# ESP32C6_RADIO register map
File version: 0.1.0
Registers are 32-bit, read-write, no defined reset value unless marked. A register's access mark holds for its fields unless they carry their own. Offsets are from the block's base; [hi:lo] are bit positions; <NAME> marks a mode.

## RFPLL — Analog I2C block 0x62 (RF PLL) The RF PLL's VCO and its calibration (the S3 has the same block). The library reads RFPLL_VCO_WINDOW after every tune and drives the LO 5/6 divider through RFPLL_LO_DIV. The capacitor code is `0x62:5 | 0x62:7[2] << 8` (9 bits; the vendor clamps to 0x1ff); a higher code means a lower VCO frequency. Some field meanings come from the S3 vendor code, as the fields and their evidence say. Upstream esp-sdr does a manual 512-code search on the ESP32-S2 through the same fields (RFPLL_MANUAL_CODE, RFPLL_MANUAL_CODE_B8, RFPLL_CODE_SRC, `0x62:0[7]`, and RFPLL_VCO_WINDOW as the window indication); it does not apply it to the S3 or the C6 (*upstream* `modules/lib/esp-sdr/main/targets/esp32s2/pll.h:8-36`). Registers 0 to 18 at 2412 MHz: `68 bb 8d 61 28 bb 0d 03 80 f0 a0 44 00 00 14 74 07 ff 60` (bench 2026-10-09). The Init rows below come from this dump.
Base 0x00006200
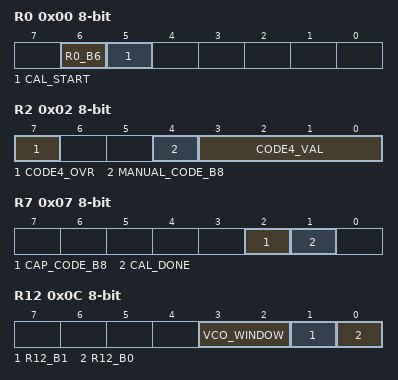
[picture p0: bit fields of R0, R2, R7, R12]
0x00 R0 8-bit — VCO calibration start Init: 0x68 Evidence: *decompile* C6 ROM `restart_cal` (0x4000587e), S3 `phy_rfpll.o`; *measured* C6 dump
  [6] R0_B6 — Unknown; toggled around the calibration start (see RFPLL_CAL_START).
  [5] CAL_START wo — `restart_cal()` starts the VCO calibration with a rising edge on this bit while RFPLL_R0_B6 is toggled: the C6 clears RFPLL_R0_B6, pulses this bit and sets RFPLL_R0_B6; the S3 sets it first and clears it after.
0x01 R1 8-bit — Manual capacitor code, bits 7:0 Init: 0xbb, the same as RFPLL_R5 (see also "Stale modem state")
  [7:0] MANUAL_CODE — Bits 7:0 of a manual capacitor code. The meaning comes from the S3 vendor code, where `write_pll_cap()` writes the code here. After a tune it holds the low byte of the code in use (on the C6 it reads as RFPLL_R5). Evidence: *decompile* S3 `phy_rfpll.o`; *measured* C6 dump
0x02 R2 8-bit — Manual code bit 8 and a 4-bit code override Init: 0x8d, read with RFPLL_R6 = 0x0d The 4-bit code override: the S3's `get_rf_freq_init()` clears RFPLL_CODE4_OVR, calibrates at 2437 MHz, copies RFPLL_CODE4_CAL into RFPLL_CODE4_VAL and sets RFPLL_CODE4_OVR. What the 4-bit code controls is unknown. Evidence: *decompile* S3 `phy_hw_freq.o` (override sequence); *measured* C6 dump
  [7] CODE4_OVR — Cleared before and set after the vendor copies the calibrated 4-bit code into RFPLL_CODE4_VAL (see below).
  [4] MANUAL_CODE_B8 — Bit 8 of the manual capacitor code, written with RFPLL_MANUAL_CODE. The meaning comes from the S3 vendor code. Evidence: *decompile* S3 `phy_rfpll.o`
  [3:0] CODE4_VAL — The 4-bit code of the override, copied from RFPLL_CODE4_CAL (see below).
0x04 R4 8-bit — Unknown Init: 0x28 (40) at every PLL frequency read, 2280 to 2438 MHz Evidence: *measured* bench 2026-10-09
0x05 R5 8-bit — Capacitor code readback, bits 7:0 Init: 0xbb
  [7:0] CAP_CODE ro — Bits 7:0 of the capacitor code; bit 8 is RFPLL_CAP_CODE_B8. Values: see "Measured PLL behaviour". Evidence: *decompile* S3 `phy_rfpll.o`; *measured*
0x06 R6 8-bit — Calibrated 4-bit code Init: 0x0d
  [3:0] CODE4_CAL ro — The calibrated 4-bit code. The vendor copies it into RFPLL_CODE4_VAL (see RFPLL_R2). Evidence: *decompile* as RFPLL_R2
0x07 R7 8-bit — Capacitor code bit 8 and calibration done Init: 0x03
  [2] CAP_CODE_B8 ro — Bit 8 of the capacitor code readback (see RFPLL_CAP_CODE). Evidence: *decompile* S3 `phy_rfpll.o`; *measured*
  [1] CAL_DONE ro — Calibration done; 1 after every tune. The S3's `wait_rfpll_cal_end()` polls it every 20 us, 100 times, then prints `error: pll_cal exceeds 2ms!!!`. Evidence: *decompile* S3 `phy_rfpll.o`; *measured*
0x0B R11 8-bit — Capacitor code source Init: 0x44
  [6] CODE_SRC — Cleared before each software calibration (`set_rfpll_freq()`), set by `rfpll_cap_init_cal()` before it tries manual codes. Inferred: 0 = code from the calibration engine, 1 = code from RFPLL_MANUAL_CODE and RFPLL_MANUAL_CODE_B8. Evidence: *decompile* C6 ROM `set_rfpll_freq` and `rfpll_cap_init_cal`, S3 `phy_rfpll.o`
0x0C R12 8-bit — VCO window comparator and two unknown status bits Init: 0x00
  [3:2] VCO_WINDOW ro — After calibration: 0 = the VCO inside its tuning window; 1 = target below the window (code pinned at its maximum); 2 = target above it (code 0). Live for the current code: the S3 vendor's `rfpll_cap_correct()` moves the code in steps of 2, up while it reads 1 and down while it reads 2. `esp_sdr_set_freq()` and `esp_sdr_set_freq_offset()` return -ERANGE when it is not 0. Window (PLL): 2140 to 2884 MHz. Evidence: *measured* bench 2026-10-09; *working* `lib/esp_sdr/src/esp_sdr.c:78-97, 194-196, 213-215`; *decompile* S3 `phy_rfpll.o`
  [1] R12_B1 ro — Unknown; set from about 2700 MHz (PLL) up, on both chips. Evidence: *measured* bench 2026-10-09
  [0] R12_B0 ro — Unknown; set below about 2412 MHz. Evidence: *measured* bench 2026-10-09
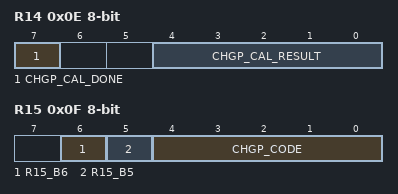
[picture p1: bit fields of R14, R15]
0x0E R14 8-bit — Charge pump calibration done and result Init: 0x14 Evidence: *decompile* C6 `libphy.a` `phy_rfpll.o` (`rfpll_chgp_cal`)
  [7] CHGP_CAL_DONE ro — Charge pump calibration done (see RFPLL_R15).
  [4:0] CHGP_CAL_RESULT ro — Charge pump calibration result (see RFPLL_R15).
0x0F R15 8-bit — Charge pump calibration Init: 0x74 `rfpll_chgp_cal()` clears RFPLL_R15_B6, pulses RFPLL_R15_B5, polls RFPLL_CHGP_CAL_DONE (20 us, 100 tries), reads r = RFPLL_CHGP_CAL_RESULT, sets RFPLL_R15_B6 and writes RFPLL_CHGP_CODE = min(31, 7r / 6 + 9). The C6 read RFPLL_R14 = 0x14 and RFPLL_R15 = 0x74 at 2412 MHz, which this formula does not produce, so the reading is incomplete or RFPLL_R14 changes later. Evidence: *decompile* C6 `libphy.a` `phy_rfpll.o` (`rfpll_chgp_cal`); *measured* C6 dump
  [6] R15_B6 — Cleared before the charge pump calibration and set after it (see below).
  [5] R15_B5 wo — Pulsed before RFPLL_CHGP_CAL_DONE is polled (see below).
  [4:0] CHGP_CODE — Written from the calibration result, min(31, 7r / 6 + 9) (see below).
0x10 R16 8-bit — LO 5/6 divider select Init: 0x07 - Change only the bit (read-modify-write). Clear it before the vendor tuning call, which calibrates in normal mode; set it after the receive front-end setup. - The library uses the divider for every frequency below 2210 MHz (PLL at 1.2 times the LO), upstream only from 1842 MHz. - A scan of the C6 blob objects found no access to `0x62:16`. - Upstream qualifies the selector on the ESP32, S2, S3, C2, C3 and C6 and warns that the C5, C61, H2 and S31 lay out their analog blocks differently. Evidence: *working* `lib/esp_sdr/src/esp_sdr.c:106-108`, `lib/esp_sdr/src/esp_sdr_rx.c:92-95` (when to clear and set) Evidence: `lib/esp_sdr/src/esp_sdr.c:65-76`, `modules/lib/esp-sdr/main/common/rx_lo.h:15-19` (divider band) Evidence: *decompile*, objdump (no access in the C6 blobs) Evidence: `modules/lib/esp-sdr/docs/rx-controls.md:102-107` (qualified chips)
  [3] LO_DIV — 0: the LO is the PLL. 1: LO = PLL / 1.2 (5/6 conversion). One selector feeds both the receive and the transmit mixer. Mask 0x08; the S3 has the same selector in block 0x65, which the C6 does not have. Evidence: *upstream* `modules/lib/esp-sdr/main/common/rx_lo.h:47-62`, external-tone tests `modules/lib/esp-sdr/docs/rx-controls.md:76-100`; *measured* on air for receive and transmit (bench 2026-10-09)
0x11 R17 8-bit — Unknown Init: 0xff at 2412 MHz; 0x7e at 2413 MHz Evidence: *measured* C6 dump
0x12 R18 8-bit — Unknown Init: 0x60 Evidence: *measured* C6 dump
